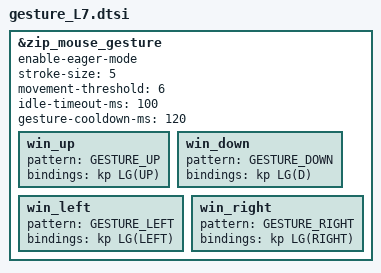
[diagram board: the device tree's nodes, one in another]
&zip_mouse_gesture {
    enable-eager-mode;
    stroke-size = <5>;
    movement-threshold = <6>;
    idle-timeout-ms = <100>;
    gesture-cooldown-ms = <120>;

    win_up    { pattern = <GESTURE_UP>;    bindings = <&kp LG(UP)>;    };
    win_down  { pattern = <GESTURE_DOWN>;  bindings = <&kp LG(D)>;     };
    win_left  { pattern = <GESTURE_LEFT>;  bindings = <&kp LG(LEFT)>;  };
    win_right { pattern = <GESTURE_RIGHT>; bindings = <&kp LG(RIGHT)>; };
};
